AUTOSAR XML (schema 00044)
package /ECUExtractIEM/VehicleProject
  system SDB12010901
    system mapping SDB12010901_MPPNG
      data-mappings:
        sender-receiver-to-signal-group-mapping={data-element=DmcStsRearToEsc.DmcStsRearToEsc, signal-group=DmcStsRearToEsc, type-mapping=sender-rec-record-type-mapping=record-element-mappings=[{application-record-element=DmcSts, system-signal=DmcStsRearToEscDmcSts}, {application-record-element=Chks, system-signal=DmcStsRearToEscChks}, {application-record-element=Cntr, system-signal=DmcStsRearToEscCntr}, {application-record-element=DmcActAppTarTq, system-signal=DmcStsRearToEscDmcActAppTarTq}, {application-record-element=DmcSWInfo, system-signal=DmcStsRearToEscDmcSWInfo}]}
        sender-receiver-to-signal-group-mapping={data-element=IemGeneric.IemGeneric, signal-group=IemGeneric, type-mapping=sender-rec-record-type-mapping=record-element-mappings=[{application-record-element=FltAlrmSt, system-signal=IemGenericFltAlrmSt}, {application-record-element=ModStatusRms, system-signal=IemGenericModStatusRms}, {application-record-element=IacAlrmSt, system-signal=IemGenericIacAlrmSt}, {application-record-element=EMSeqNr, system-signal=IemGenericEMSeqNr}, {application-record-element=SpdAlrmSt, system-signal=IemGenericSpdAlrmSt}, {application-record-element=MotTAlrmSt, system-signal=IemGenericMotTAlrmSt}, {application-record-element=UDcAlrmSt, system-signal=IemGenericUDcAlrmSt}, {application-record-element=EMQnty, system-signal=IemGenericEMQnty}, {application-record-element=InvrtTAlrmSt, system-signal=IemGenericInvrtTAlrmSt}, {application-record-element=ADAlrmSt, system-signal=IemGenericADAlrmSt}, {application-record-element=DTCHig, system-signal=IemGenericDTCHig}, {application-record-element=DTCLow, system-signal=IemGenericDTCLow}, {application-record-element=RslAlrmSt, system-signal=IemGenericRslAlrmSt}, {application-record-element=DTCMid, system-signal=IemGenericDTCMid}, {application-record-element=DTCSts, system-signal=IemGenericDTCSts}, {application-record-element=TypeInfo, system-signal=IemGenericTypeInfo}]}
        sender-receiver-to-signal-group-mapping={data-element=IEMTestFr1.IEMTestFr1, signal-group=IEMTestFr1, type-mapping=sender-rec-record-type-mapping=record-element-mappings=[{application-record-element=Byte7, system-signal=IEMTestFr1Byte7}, {application-record-element=Byte2, system-signal=IEMTestFr1Byte2}, {application-record-element=Byte6, system-signal=IEMTestFr1Byte6}, {application-record-element=Byte4, system-signal=IEMTestFr1Byte4}, {application-record-element=Byte3, system-signal=IEMTestFr1Byte3}, {application-record-element=Byte1, system-signal=IEMTestFr1Byte1}, {application-record-element=Byte0, system-signal=IEMTestFr1Byte0}, {application-record-element=Byte5, system-signal=IEMTestFr1Byte5}]}
        sender-receiver-to-signal-group-mapping={data-element=IEMTestFr2.IEMTestFr2, signal-group=IEMTestFr2, type-mapping=sender-rec-record-type-mapping=record-element-mappings=[{application-record-element=Byte2, system-signal=IEMTestFr2Byte2}, {application-record-element=Byte3, system-signal=IEMTestFr2Byte3}, {application-record-element=Byte5, system-signal=IEMTestFr2Byte5}, {application-record-element=Byte7, system-signal=IEMTestFr2Byte7}, {application-record-element=Byte6, system-signal=IEMTestFr2Byte6}, {application-record-element=Byte4, system-signal=IEMTestFr2Byte4}, {application-record-element=Byte1, system-signal=IEMTestFr2Byte1}, {application-record-element=Byte0, system-signal=IEMTestFr2Byte0}]}
        sender-receiver-to-signal-group-mapping={data-element=IEMTestFr3.IEMTestFr3, signal-group=IEMTestFr3, type-mapping=sender-rec-record-type-mapping=record-element-mappings=[{application-record-element=Byte0, system-signal=IEMTestFr3Byte0}, {application-record-element=Byte4, system-signal=IEMTestFr3Byte4}, {application-record-element=Byte5, system-signal=IEMTestFr3Byte5}, {application-record-element=Byte6, system-signal=IEMTestFr3Byte6}, {application-record-element=Byte1, system-signal=IEMTestFr3Byte1}, {application-record-element=Byte7, system-signal=IEMTestFr3Byte7}, {application-record-element=Byte2, system-signal=IEMTestFr3Byte2}, {application-record-element=Byte3, system-signal=IEMTestFr3Byte3}]}
        sender-receiver-to-signal-group-mapping={data-element=ImobEngChk2.ImobEngChk2, signal-group=ImobEngChk2, type-mapping=sender-rec-record-type-mapping=record-element-mappings=[{application-record-element=ImobEngDataChk2, system-signal=ImobEngChk2ImobEngDataChk2}, {application-record-element=ImobEngDataChk3, system-signal=ImobEngChk2ImobEngDataChk3}, {application-record-element=ImobEngDataChk4, system-signal=ImobEngChk2ImobEngDataChk4}, {application-record-element=ImobEngDataChk6, system-signal=ImobEngChk2ImobEngDataChk6}, {application-record-element=ImobEngChkSts, system-signal=ImobEngChk2ImobEngChkSts}, {application-record-element=ImobEngDataChk0, system-signal=ImobEngChk2ImobEngDataChk0}, {application-record-element=ImobEngDataChk5, system-signal=ImobEngChk2ImobEngDataChk5}, {application-record-element=ImobEngDataChk1, system-signal=ImobEngChk2ImobEngDataChk1}]}
        sender-receiver-to-signal-mapping={data-element=ImobEngSts2.ImobEngSts2, system-signal=ImobEngSts2}
        sender-receiver-to-signal-mapping={data-element=PLockFltIndcRe.PLockFltIndcRe, system-signal=PLockFltIndcRe}
        sender-receiver-to-signal-mapping={data-element=PLockFltLvlRe.PLockFltLvlRe, system-signal=PLockFltLvlRe}
        sender-receiver-to-signal-mapping={data-element=PLockParkStsRe.PLockParkStsRe, system-signal=PLockParkStsRe}
        sender-receiver-to-signal-mapping={data-element=WhlMotClrRdyReq.WhlMotClrRdyReq, system-signal=WhlMotClrRdyReq}
        sender-receiver-to-signal-mapping={data-element=WhlMotCooltFlowMinReq.WhlMotCooltFlowMinReq, system-signal=WhlMotCooltFlowMinReq}
        sender-receiver-to-signal-mapping={data-element=WhlMotSysCoolgReq.WhlMotSysCoolgReq, system-signal=WhlMotSysCoolgReq}
        sender-receiver-to-signal-mapping={data-element=WhlMotSysCooltT.WhlMotSysCooltT, system-signal=WhlMotSysCooltT}
        sender-receiver-to-signal-mapping={data-element=WhlMotSysErrIndcnReq.WhlMotSysErrIndcnReq, system-signal=WhlMotSysErrIndcnReq}
        sender-receiver-to-signal-mapping={data-element=WhlMotSysHeatFdBck.WhlMotSysHeatFdBck, system-signal=WhlMotSysHeatFdBck}
        sender-receiver-to-signal-mapping={data-element=WhlMotSysHeatPwrAct.WhlMotSysHeatPwrAct, system-signal=WhlMotSysHeatPwrAct}
        sender-receiver-to-signal-mapping={data-element=WhlMotSysHeatPwrMax.WhlMotSysHeatPwrMax, system-signal=WhlMotSysHeatPwrMax}
        sender-receiver-to-signal-mapping={data-element=WhlMotSysIdc.WhlMotSysIdc, system-signal=WhlMotSysIdc}
        sender-receiver-to-signal-mapping={data-element=WhlMotSysInvrT.WhlMotSysInvrT, system-signal=WhlMotSysInvrT}
        sender-receiver-to-signal-mapping={data-element=WhlMotSysLimnIndcn.WhlMotSysLimnIndcn, system-signal=WhlMotSysLimnIndcn}
        sender-receiver-to-signal-mapping={data-element=WhlMotSysModSts.WhlMotSysModSts, system-signal=WhlMotSysModSts}
        sender-receiver-to-signal-mapping={data-element=WhlMotSysMotT.WhlMotSysMotT, system-signal=WhlMotSysMotT}
        sender-receiver-to-signal-mapping={data-element=WhlMotSysSpdAct.WhlMotSysSpdAct, system-signal=WhlMotSysSpdAct}
        sender-receiver-to-signal-group-mapping={data-element=WhlMotSysSpdActSafe.WhlMotSysSpdActSafe, signal-group=WhlMotSysSpdActSafe, type-mapping=sender-rec-record-type-mapping=record-element-mappings=[{application-record-element=Chks, system-signal=WhlMotSysSpdActSafeChks}, {application-record-element=IsgSpdWSgnTyp, system-signal=WhlMotSysSpdActSafeIsgSpdWSgnTyp}, {application-record-element=Qf, system-signal=WhlMotSysSpdActSafeQf}, {application-record-element=Cntr, system-signal=WhlMotSysSpdActSafeCntr}]}
        sender-receiver-to-signal-group-mapping={data-element=WhlMotSysTqAvl.WhlMotSysTqAvl, signal-group=WhlMotSysTqAvl, type-mapping=sender-rec-record-type-mapping=record-element-mappings=[{application-record-element=TqAvlMin, system-signal=WhlMotSysTqAvlTqAvlMin}, {application-record-element=TqAvlMax, system-signal=WhlMotSysTqAvlTqAvlMax}]}
        sender-receiver-to-signal-group-mapping={data-element=WhlMotSysTqEst.WhlMotSysTqEst, signal-group=WhlMotSysTqEst, type-mapping=sender-rec-record-type-mapping=record-element-mappings=[{application-record-element=Cntr, system-signal=WhlMotSysTqEstCntr}, {application-record-element=IsgTqAct, system-signal=WhlMotSysTqEstIsgTqAct}, {application-record-element=QualityFactor, system-signal=WhlMotSysTqEstQualityFactor}, {application-record-element=Chks, system-signal=WhlMotSysTqEstChks}]}
        sender-receiver-to-signal-mapping={data-element=WhlMotSysUdc.WhlMotSysUdc, system-signal=WhlMotSysUdc}
        sender-receiver-to-signal-mapping={data-element=BkpOfDstTrvld.BkpOfDstTrvld, system-signal=BkpOfDstTrvld}
        sender-receiver-to-signal-mapping={data-element=CarTiGlb.CarTiGlb, system-signal=CarTiGlb}
        sender-receiver-to-signal-mapping={data-element=CooltFlowForDtElec.CooltFlowForDtElec, system-signal=CooltFlowForDtElec}
        sender-receiver-to-signal-mapping={data-element=CooltTSigForDtElec.CooltTSigForDtElec, system-signal=CooltTSigForDtElec}
        sender-receiver-to-signal-group-mapping={data-element=CrashStsSafe.CrashStsSafe, signal-group=CrashStsSafe, type-mapping=sender-rec-record-type-mapping=record-element-mappings=[{application-record-element=Cntr, system-signal=CrashStsSafeCntr}, {application-record-element=Sts, system-signal=CrashStsSafeSts}, {application-record-element=Chks, system-signal=CrashStsSafeChks}]}
        sender-receiver-to-signal-mapping={data-element=DCChrgnHndlSts.DCChrgnHndlSts, system-signal=DCChrgnHndlSts}
        sender-receiver-to-signal-mapping={data-element=DrvgCyc.DrvgCyc, system-signal=DrvgCyc}
        sender-receiver-to-signal-group-mapping={data-element=EngSt1WdSts.EngSt1WdSts, signal-group=EngSt1WdSts, type-mapping=sender-rec-record-type-mapping=record-element-mappings=[{application-record-element=Chks, system-signal=EngSt1WdStsChks}, {application-record-element=EngSt1WdSts, system-signal=EngSt1WdStsEngSt1WdSts}, {application-record-element=Cntr, system-signal=EngSt1WdStsCntr}]}
        sender-receiver-to-signal-group-mapping={data-element=EscVariantToDmc.EscVariantToDmc, signal-group=EscVariantToDmc, type-mapping=sender-rec-record-type-mapping=record-element-mappings=[{application-record-element=Chks, system-signal=EscVariantToDmcChks}, {application-record-element=EscVariantToDmc, system-signal=EscVariantToDmcEscVariantToDmc}, {application-record-element=Cntr, system-signal=EscVariantToDmcCntr}]}
        sender-receiver-to-signal-mapping={data-element=GearLvrIndcn.GearLvrIndcn, system-signal=GearLvrIndcn}
        sender-receiver-to-signal-mapping={data-element=HvBattSoc.HvBattSoc, system-signal=HvBattSoc}
        sender-receiver-to-signal-mapping={data-element=HvBattUDc.HvBattUDc, system-signal=HvBattUDc}
        sender-receiver-to-signal-mapping={data-element=HvBattUDynMaxLim.HvBattUDynMaxLim, system-signal=HvBattUDynMaxLim}
        sender-receiver-to-signal-mapping={data-element=HvBattUDynMinLim.HvBattUDynMinLim, system-signal=HvBattUDynMinLim}
        sender-receiver-to-signal-group-mapping={data-element=HvSysRlySts.HvSysRlySts, signal-group=HvSysRlySts, type-mapping=sender-rec-record-type-mapping=record-element-mappings=[{application-record-element=Chks, system-signal=HvSysRlyStsChks}, {application-record-element=HvSysRlySts, system-signal=HvSysRlyStsHvSysRlySts}, {application-record-element=Cntr, system-signal=HvSysRlyStsCntr}]}
        sender-receiver-to-signal-group-mapping={data-element=ImobEngMgrReq2.ImobEngMgrReq2, signal-group=ImobEngMgrReq2, type-mapping=sender-rec-record-type-mapping=record-element-mappings=[{application-record-element=ImobEngDataMgrReq4, system-signal=ImobEngMgrReq2ImobEngDataMgrReq4}, {application-record-element=ImobEngMgrCmdTar1, system-signal=ImobEngMgrReq2ImobEngMgrCmdTar1}, {application-record-element=ImobEngDataMgrReq3, system-signal=ImobEngMgrReq2ImobEngDataMgrReq3}, {application-record-element=ImobEngDataMgrReq2, system-signal=ImobEngMgrReq2ImobEngDataMgrReq2}, {application-record-element=ImobEngDataMgrReq0, system-signal=ImobEngMgrReq2ImobEngDataMgrReq0}, {application-record-element=ImobEngDataMgrReq5, system-signal=ImobEngMgrReq2ImobEngDataMgrReq5}, {application-record-element=ImobEngDataMgrReq6, system-signal=ImobEngMgrReq2ImobEngDataMgrReq6}, {application-record-element=ImobEngDataMgrReq1, system-signal=ImobEngMgrReq2ImobEngDataMgrReq1}]}
        sender-receiver-to-signal-mapping={data-element=OnBdChrgrHndlSts1.OnBdChrgrHndlSts1, system-signal=OnBdChrgrHndlSts1}
        sender-receiver-to-signal-mapping={data-element=PLockParkReq.PLockParkReq, system-signal=PLockParkReq}
        sender-receiver-to-signal-mapping={data-element=PrpsnFbLimnIndcn.PrpsnFbLimnIndcn, system-signal=PrpsnFbLimnIndcn}
        sender-receiver-to-signal-group-mapping={data-element=PtTqAtAxleMaxReq.PtTqAtAxleMaxReq, signal-group=PtTqAtAxleMaxReq, type-mapping=sender-rec-record-type-mapping=record-element-mappings=[{application-record-element=Chks, system-signal=PtTqAtAxleMaxReqChks}, {application-record-element=PtTqAtAxleFrntReq, system-signal=PtTqAtAxleMaxReqPtTqAtAxleFrntReq}, {application-record-element=Cntr, system-signal=PtTqAtAxleMaxReqCntr}, {application-record-element=PtTqAtAxleReReq, system-signal=PtTqAtAxleMaxReqPtTqAtAxleReReq}]}
        sender-receiver-to-signal-mapping={data-element=RearHeatModEnad.RearHeatModEnad, system-signal=RearHeatModEnad}
        sender-receiver-to-signal-mapping={data-element=RearHeatPwrAllwd.RearHeatPwrAllwd, system-signal=RearHeatPwrAllwd}
        sender-receiver-to-signal-mapping={data-element=SpdRotlForWhlsAtAxleRe.SpdRotlForWhlsAtAxleRe, system-signal=SpdRotlForWhlsAtAxleRe}
        sender-receiver-to-signal-group-mapping={data-element=StcStsToDmc.StcStsToDmc, signal-group=StcStsToDmc, type-mapping=sender-rec-record-type-mapping=record-element-mappings=[{application-record-element=EngRotTarSpdDMCFrnt, system-signal=StcStsToDmcEngRotTarSpdDMCFrnt}, {application-record-element=StcStsToDmcFrnt, system-signal=StcStsToDmcFrnt}, {application-record-element=EngRotTarSpdDMCRear, system-signal=StcStsToDmcEngRotTarSpdDMCRear}, {application-record-element=Chks, system-signal=StcStsToDmcChks}, {application-record-element=Cntr, system-signal=StcStsToDmcCntr}, {application-record-element=StcStsToDmcRear, system-signal=StcStsToDmcRear}]}
        sender-receiver-to-signal-group-mapping={data-element=VehBattU.VehBattU, signal-group=VehBattU, type-mapping=sender-rec-record-type-mapping=record-element-mappings=[{application-record-element=SysU, system-signal=VehBattUSysU}, {application-record-element=SysUQf, system-signal=VehBattUSysUQf}]}
        sender-receiver-to-signal-group-mapping={data-element=VehCfgPrm.VehCfgPrm, signal-group=VehCfgPrm, type-mapping=sender-rec-record-type-mapping=record-element-mappings=[{application-record-element=CCPBytePosn6, system-signal=VehCfgPrmCCPBytePosn6}, {application-record-element=BlkIDBytePosn1, system-signal=VehCfgPrmBlkIDBytePosn1}, {application-record-element=CCPBytePosn4, system-signal=VehCfgPrmCCPBytePosn4}, {application-record-element=CCPBytePosn3, system-signal=VehCfgPrmCCPBytePosn3}, {application-record-element=CCPBytePosn2, system-signal=VehCfgPrmCCPBytePosn2}, {application-record-element=CCPBytePosn8, system-signal=VehCfgPrmCCPBytePosn8}, {application-record-element=CCPBytePosn7, system-signal=VehCfgPrmCCPBytePosn7}, {application-record-element=CCPBytePosn5, system-signal=VehCfgPrmCCPBytePosn5}]}
        sender-receiver-to-signal-group-mapping={data-element=VehCfgPrmExt.VehCfgPrmExt, signal-group=VehCfgPrmExt, type-mapping=sender-rec-record-type-mapping=record-element-mappings=[{application-record-element=CCPBytePosn5, system-signal=VehCfgPrmExtCCPBytePosn5}, {application-record-element=CCPBytePosn6, system-signal=VehCfgPrmExtCCPBytePosn6}, {application-record-element=CCPBytePosn2, system-signal=VehCfgPrmExtCCPBytePosn2}, {application-record-element=CCPBytePosn3, system-signal=VehCfgPrmExtCCPBytePosn3}, {application-record-element=CCPBytePosn8, system-signal=VehCfgPrmExtCCPBytePosn8}, {application-record-element=CCPBytePosn4, system-signal=VehCfgPrmExtCCPBytePosn4}, {application-record-element=CCPBytePosn7, system-signal=VehCfgPrmExtCCPBytePosn7}, {application-record-element=BlkIDBytePosn1, system-signal=VehCfgPrmExtBlkIDBytePosn1}]}
        sender-receiver-to-signal-group-mapping={data-element=VehModMngtGlbSafe1.VehModMngtGlbSafe1, signal-group=VehModMngtGlbSafe1, type-mapping=sender-rec-record-type-mapping=record-element-mappings=[{application-record-element=Chks, system-signal=VehModMngtGlbSafe1Chks}, {application-record-element=CarModSts1, system-signal=VehModMngtGlbSafe1CarModSts1}, {application-record-element=Cntr, system-signal=VehModMngtGlbSafe1Cntr}, {application-record-element=EgyLvlElecSubtyp, system-signal=VehModMngtGlbSafe1EgyLvlElecSubtyp}, {application-record-element=PwrLvlElecSubtyp, system-signal=VehModMngtGlbSafe1PwrLvlElecSubtyp}, {application-record-element=CarModSubtypWdCarModSubtyp, system-signal=VehModMngtGlbSafe1CarModSubtypWdCarModSubtyp}, {application-record-element=UsgModSts, system-signal=VehModMngtGlbSafe1UsgModSts}, {application-record-element=PwrLvlElecMai, system-signal=VehModMngtGlbSafe1PwrLvlElecMai}, {application-record-element=EgyLvlElecMai, system-signal=VehModMngtGlbSafe1EgyLvlElecMai}, {application-record-element=FltEgyCnsWdSts, system-signal=VehModMngtGlbSafe1FltEgyCnsWdSts}]}
        sender-receiver-to-signal-group-mapping={data-element=VehMtnSt.VehMtnSt, signal-group=VehMtnSt, type-mapping=sender-rec-record-type-mapping=record-element-mappings=[{application-record-element=VehMtnStChks, system-signal=VehMtnStChks}, {application-record-element=VehMtnStCntr, system-signal=VehMtnStCntr}, {application-record-element=VehMtnSt, system-signal=VehMtnStVehMtnSt}]}
        sender-receiver-to-signal-group-mapping={data-element=VehSpdLgt.VehSpdLgt, signal-group=VehSpdLgt, type-mapping=sender-rec-record-type-mapping=record-element-mappings=[{application-record-element=VehSpdLgtQf, system-signal=VehSpdLgtQf}, {application-record-element=VehSpdLgtCntr, system-signal=VehSpdLgtCntr}, {application-record-element=VehSpdLgtChks, system-signal=VehSpdLgtChks}, {application-record-element=VehSpdLgtA, system-signal=VehSpdLgtA}]}
        sender-receiver-to-signal-mapping={data-element=WhlMotSysActvDampgModReq.WhlMotSysActvDampgModReq, system-signal=WhlMotSysActvDampgModReq}
        sender-receiver-to-signal-mapping={data-element=WhlMotSysModReq.WhlMotSysModReq, system-signal=WhlMotSysModReq}
        sender-receiver-to-signal-mapping={data-element=WhlMotSysPwrLimMax.WhlMotSysPwrLimMax, system-signal=WhlMotSysPwrLimMax}
        sender-receiver-to-signal-mapping={data-element=WhlMotSysPwrLimMin.WhlMotSysPwrLimMin, system-signal=WhlMotSysPwrLimMin}
        sender-receiver-to-signal-group-mapping={data-element=WhlMotSysTqAllwd.WhlMotSysTqAllwd, signal-group=WhlMotSysTqAllwd, type-mapping=sender-rec-record-type-mapping=record-element-mappings=[{application-record-element=WhlMotSysTqAllwd, system-signal=WhlMotSysTqAllwdWhlMotSysTqAllwd}, {application-record-element=Chks, system-signal=WhlMotSysTqAllwdChks}, {application-record-element=Cntr, system-signal=WhlMotSysTqAllwdCntr}]}
        sender-receiver-to-signal-mapping={data-element=WhlMotSysTqReq.WhlMotSysTqReq, system-signal=WhlMotSysTqReq}
      pnc-mappings:
        pnc-group=TxSPG_PropulsionCAN_PNC16, pnc-identifier=16, vfc=TopLevelComposition.InfotainmentPush
        pnc-group=[TxSPG_PropulsionCAN_PNC24, RxSPG_PropulsionCAN_PNC24], pnc-identifier=24, vfc=TopLevelComposition.PropulsionStart
        pnc-group=[TxSPG_PropulsionCAN_PNC25, RxSPG_PropulsionCAN_PNC25], pnc-identifier=25, vfc=TopLevelComposition.ChargingHV
        pnc-group=[TxSPG_PropulsionCAN_PNC26, RxSPG_PropulsionCAN_PNC26], pnc-identifier=26, vfc=[TopLevelComposition.ParkingDrivingClimatization, TopLevelComposition.Immobilizer]
        pnc-group=[TxSPG_PropulsionCAN_PNC27, RxSPG_PropulsionCAN_PNC27], pnc-identifier=27, vfc=TopLevelComposition.TelematicsConnectivity
        pnc-group=[TxSPG_PropulsionCAN_PNC29, RxSPG_PropulsionCAN_PNC29], pnc-identifier=29, vfc=[TopLevelComposition.Diagnostics, TopLevelComposition.VehicleDriving, TopLevelComposition.VehicleModeManagement]
        pnc-group=[TxSPG_PropulsionCAN_PNC30, RxSPG_PropulsionCAN_PNC30], pnc-identifier=30, vfc=TopLevelComposition.GlobalShortDuration
        pnc-group=TxSPG_PropulsionCAN_PNC33, pnc-identifier=33, vfc=TopLevelComposition.Brake
        pnc-group=[TxSPG_PropulsionCAN_PNC35, RxSPG_PropulsionCAN_PNC35], pnc-identifier=35, vfc=TopLevelComposition.HVEnergyStorage
        pnc-group=[TxSPG_PropulsionCAN_PNC39, RxSPG_PropulsionCAN_PNC39], pnc-identifier=39, vfc=TopLevelComposition.Crash
    root-software-compositions:
      root sw composition prototype TopLevelComposition: software-composition=TopLevelComposition
package /ECUExtractIEM/ComponentType
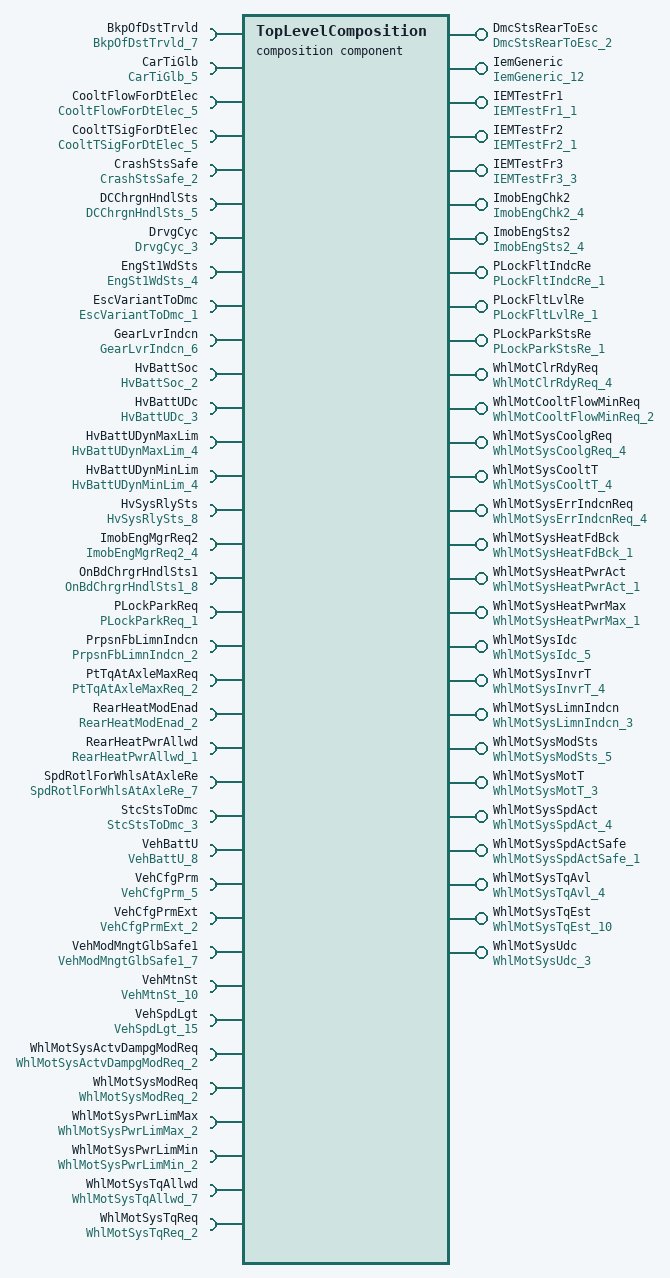
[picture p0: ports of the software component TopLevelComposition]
  composition sw component type TopLevelComposition
    28 x provide port:
      DmcStsRearToEsc: provided-interface=DmcStsRearToEsc_2
      IemGeneric: provided-interface=IemGeneric_12
      IEMTestFr1: provided-interface=IEMTestFr1_1
      IEMTestFr2: provided-interface=IEMTestFr2_1
      IEMTestFr3: provided-interface=IEMTestFr3_3
      ImobEngChk2: provided-interface=ImobEngChk2_4
      ImobEngSts2: provided-interface=ImobEngSts2_4
      PLockFltIndcRe: provided-interface=PLockFltIndcRe_1
      PLockFltLvlRe: provided-interface=PLockFltLvlRe_1
      PLockParkStsRe: provided-interface=PLockParkStsRe_1
      WhlMotClrRdyReq: provided-interface=WhlMotClrRdyReq_4
      WhlMotCooltFlowMinReq: provided-interface=WhlMotCooltFlowMinReq_2
      WhlMotSysCoolgReq: provided-interface=WhlMotSysCoolgReq_4
      WhlMotSysCooltT: provided-interface=WhlMotSysCooltT_4
      WhlMotSysErrIndcnReq: provided-interface=WhlMotSysErrIndcnReq_4
      WhlMotSysHeatFdBck: provided-interface=WhlMotSysHeatFdBck_1
      WhlMotSysHeatPwrAct: provided-interface=WhlMotSysHeatPwrAct_1
      WhlMotSysHeatPwrMax: provided-interface=WhlMotSysHeatPwrMax_1
      WhlMotSysIdc: provided-interface=WhlMotSysIdc_5
      WhlMotSysInvrT: provided-interface=WhlMotSysInvrT_4
      WhlMotSysLimnIndcn: provided-interface=WhlMotSysLimnIndcn_3
      WhlMotSysModSts: provided-interface=WhlMotSysModSts_5
      WhlMotSysMotT: provided-interface=WhlMotSysMotT_3
      WhlMotSysSpdAct: provided-interface=WhlMotSysSpdAct_4
      WhlMotSysSpdActSafe: provided-interface=WhlMotSysSpdActSafe_1
      WhlMotSysTqAvl: provided-interface=WhlMotSysTqAvl_4
      WhlMotSysTqEst: provided-interface=WhlMotSysTqEst_10
      WhlMotSysUdc: provided-interface=WhlMotSysUdc_3
    36 x require port:
      BkpOfDstTrvld: required-interface=BkpOfDstTrvld_7
      CarTiGlb: required-interface=CarTiGlb_5
      CooltFlowForDtElec: required-interface=CooltFlowForDtElec_5
      CooltTSigForDtElec: required-interface=CooltTSigForDtElec_5
      CrashStsSafe: required-interface=CrashStsSafe_2
      DCChrgnHndlSts: required-interface=DCChrgnHndlSts_5
      DrvgCyc: required-interface=DrvgCyc_3
      EngSt1WdSts: required-interface=EngSt1WdSts_4
      EscVariantToDmc: required-interface=EscVariantToDmc_1
      GearLvrIndcn: required-interface=GearLvrIndcn_6
      HvBattSoc: required-interface=HvBattSoc_2
      HvBattUDc: required-interface=HvBattUDc_3
      HvBattUDynMaxLim: required-interface=HvBattUDynMaxLim_4
      HvBattUDynMinLim: required-interface=HvBattUDynMinLim_4
      HvSysRlySts: required-interface=HvSysRlySts_8
      ImobEngMgrReq2: required-interface=ImobEngMgrReq2_4
      OnBdChrgrHndlSts1: required-interface=OnBdChrgrHndlSts1_8
      PLockParkReq: required-interface=PLockParkReq_1
      PrpsnFbLimnIndcn: required-interface=PrpsnFbLimnIndcn_2
      PtTqAtAxleMaxReq: required-interface=PtTqAtAxleMaxReq_2
      RearHeatModEnad: required-interface=RearHeatModEnad_2
      RearHeatPwrAllwd: required-interface=RearHeatPwrAllwd_1
      SpdRotlForWhlsAtAxleRe: required-interface=SpdRotlForWhlsAtAxleRe_7
      StcStsToDmc: required-interface=StcStsToDmc_3
      VehBattU: required-interface=VehBattU_8
      VehCfgPrm: required-interface=VehCfgPrm_5
      VehCfgPrmExt: required-interface=VehCfgPrmExt_2
      VehModMngtGlbSafe1: required-interface=VehModMngtGlbSafe1_7
      VehMtnSt: required-interface=VehMtnSt_10
      VehSpdLgt: required-interface=VehSpdLgt_15
      WhlMotSysActvDampgModReq: required-interface=WhlMotSysActvDampgModReq_2
      WhlMotSysModReq: required-interface=WhlMotSysModReq_2
      WhlMotSysPwrLimMax: required-interface=WhlMotSysPwrLimMax_2
      WhlMotSysPwrLimMin: required-interface=WhlMotSysPwrLimMin_2
      WhlMotSysTqAllwd: required-interface=WhlMotSysTqAllwd_7
      WhlMotSysTqReq: required-interface=WhlMotSysTqReq_2
    13 x port group, all with category=PARTIAL_NETWORKING:
      ParkingDrivingClimatization: inner-group=IEM.ParkingDrivingClimatization
      Diagnostics: inner-group=IEM.Diagnostics
      VehicleDriving: inner-group=IEM.VehicleDriving
      VehicleModeManagement: inner-group=IEM.VehicleModeManagement
      TelematicsConnectivity: inner-group=IEM.TelematicsConnectivity
      HVEnergyStorage: inner-group=IEM.HVEnergyStorage
      Crash: inner-group=IEM.Crash
      InfotainmentPush: inner-group=IEM.InfotainmentPush
      PropulsionStart: inner-group=IEM.PropulsionStart
      GlobalShortDuration: inner-group=IEM.GlobalShortDuration
      Brake: inner-group=IEM.Brake
      ChargingHV: inner-group=IEM.ChargingHV
      Immobilizer: inner-group=IEM.Immobilizer
    component IEM: type=IEM
    delegate IEM.DmcStsRearToEsc <-> outer port DmcStsRearToEsc
    delegate IEM.IemGeneric <-> outer port IemGeneric
    delegate IEM.IEMTestFr{1..3} <-> outer port IEMTestFr{1..3}
    delegate IEM.ImobEngChk2 <-> outer port ImobEngChk2
    delegate IEM.ImobEngSts2 <-> outer port ImobEngSts2
    delegate IEM.PLockFltIndcRe <-> outer port PLockFltIndcRe
    delegate IEM.PLockFltLvlRe <-> outer port PLockFltLvlRe
    delegate IEM.PLockParkStsRe <-> outer port PLockParkStsRe
    delegate IEM.WhlMotClrRdyReq <-> outer port WhlMotClrRdyReq
    delegate IEM.WhlMotCooltFlowMinReq <-> outer port WhlMotCooltFlowMinReq
    delegate IEM.WhlMotSysCoolgReq <-> outer port WhlMotSysCoolgReq
    delegate IEM.WhlMotSysCooltT <-> outer port WhlMotSysCooltT
    delegate IEM.WhlMotSysErrIndcnReq <-> outer port WhlMotSysErrIndcnReq
    delegate IEM.WhlMotSysHeatFdBck <-> outer port WhlMotSysHeatFdBck
    delegate IEM.WhlMotSysHeatPwrAct <-> outer port WhlMotSysHeatPwrAct
    delegate IEM.WhlMotSysHeatPwrMax <-> outer port WhlMotSysHeatPwrMax
    delegate IEM.WhlMotSysIdc <-> outer port WhlMotSysIdc
    delegate IEM.WhlMotSysInvrT <-> outer port WhlMotSysInvrT
    delegate IEM.WhlMotSysLimnIndcn <-> outer port WhlMotSysLimnIndcn
    delegate IEM.WhlMotSysModSts <-> outer port WhlMotSysModSts
    delegate IEM.WhlMotSysMotT <-> outer port WhlMotSysMotT
    delegate IEM.WhlMotSysSpdAct <-> outer port WhlMotSysSpdAct
    delegate IEM.WhlMotSysSpdActSafe <-> outer port WhlMotSysSpdActSafe
    delegate IEM.WhlMotSysTqAvl <-> outer port WhlMotSysTqAvl
    delegate IEM.WhlMotSysTqEst <-> outer port WhlMotSysTqEst
    delegate IEM.WhlMotSysUdc <-> outer port WhlMotSysUdc
    delegate IEM.BkpOfDstTrvld <-> outer port BkpOfDstTrvld
    delegate IEM.CarTiGlb <-> outer port CarTiGlb
    delegate IEM.CooltFlowForDtElec <-> outer port CooltFlowForDtElec
    delegate IEM.CooltTSigForDtElec <-> outer port CooltTSigForDtElec
    delegate IEM.CrashStsSafe <-> outer port CrashStsSafe
    delegate IEM.DCChrgnHndlSts <-> outer port DCChrgnHndlSts
    delegate IEM.DrvgCyc <-> outer port DrvgCyc
    delegate IEM.EngSt1WdSts <-> outer port EngSt1WdSts
    delegate IEM.EscVariantToDmc <-> outer port EscVariantToDmc
    delegate IEM.GearLvrIndcn <-> outer port GearLvrIndcn
    delegate IEM.HvBattSoc <-> outer port HvBattSoc
    delegate IEM.HvBattUDc <-> outer port HvBattUDc
    delegate IEM.HvBattUDynMaxLim <-> outer port HvBattUDynMaxLim
    delegate IEM.HvBattUDynMinLim <-> outer port HvBattUDynMinLim
    delegate IEM.HvSysRlySts <-> outer port HvSysRlySts
    delegate IEM.ImobEngMgrReq2 <-> outer port ImobEngMgrReq2
    delegate IEM.OnBdChrgrHndlSts1 <-> outer port OnBdChrgrHndlSts1
    delegate IEM.PLockParkReq <-> outer port PLockParkReq
    delegate IEM.PrpsnFbLimnIndcn <-> outer port PrpsnFbLimnIndcn
    delegate IEM.PtTqAtAxleMaxReq <-> outer port PtTqAtAxleMaxReq
    delegate IEM.RearHeatModEnad <-> outer port RearHeatModEnad
    delegate IEM.RearHeatPwrAllwd <-> outer port RearHeatPwrAllwd
    delegate IEM.SpdRotlForWhlsAtAxleRe <-> outer port SpdRotlForWhlsAtAxleRe
    delegate IEM.StcStsToDmc <-> outer port StcStsToDmc
    delegate IEM.VehBattU <-> outer port VehBattU
    delegate IEM.VehCfgPrm <-> outer port VehCfgPrm
    delegate IEM.VehCfgPrmExt <-> outer port VehCfgPrmExt
    delegate IEM.VehModMngtGlbSafe1 <-> outer port VehModMngtGlbSafe1
    delegate IEM.VehMtnSt <-> outer port VehMtnSt
    delegate IEM.VehSpdLgt <-> outer port VehSpdLgt
    delegate IEM.WhlMotSysActvDampgModReq <-> outer port WhlMotSysActvDampgModReq
    delegate IEM.WhlMotSysModReq <-> outer port WhlMotSysModReq
    delegate IEM.WhlMotSysPwrLimMax <-> outer port WhlMotSysPwrLimMax
    delegate IEM.WhlMotSysPwrLimMin <-> outer port WhlMotSysPwrLimMin
    delegate IEM.WhlMotSysTqAllwd <-> outer port WhlMotSysTqAllwd
    delegate IEM.WhlMotSysTqReq <-> outer port WhlMotSysTqReq
package /EndToEnds
  end to end protection set MainEndToEndSet
    10 x end to end protection, all with end-to-end-profile=category=PROFILE_G:
      HvSysRlySts_BECM1_IEM: end-to-end-protection-variable-prototype=receiver=TopLevelComposition.HvSysRlySts.HvSysRlySts
      WhlMotSysTqAllwd_ECM3_IEM: end-to-end-protection-variable-prototype=receiver=TopLevelComposition.WhlMotSysTqAllwd.WhlMotSysTqAllwd
      DmcStsRearToEsc_IEM_VDDM: end-to-end-protection-variable-prototype=TopLevelComposition.DmcStsRearToEsc.DmcStsRearToEsc
      WhlMotSysTqEst_IEM_ECM3: end-to-end-protection-variable-prototype=TopLevelComposition.WhlMotSysTqEst.WhlMotSysTqEst
      WhlMotSysSpdActSafe_IEM_BBMRoot: end-to-end-protection-variable-prototype=TopLevelComposition.WhlMotSysSpdActSafe.WhlMotSysSpdActSafe
      CrashStsSafe_SRS_IEM: end-to-end-protection-variable-prototype=receiver=TopLevelComposition.CrashStsSafe.CrashStsSafe
      VehMtnSt_VDDM_IEM: end-to-end-protection-variable-prototype=receiver=TopLevelComposition.VehMtnSt.VehMtnSt
      VehSpdLgt_VDDM_IEM: end-to-end-protection-variable-prototype=receiver=TopLevelComposition.VehSpdLgt.VehSpdLgt
      StcStsToDmc_VDDM_IEM: end-to-end-protection-variable-prototype=receiver=TopLevelComposition.StcStsToDmc.StcStsToDmc
      EscVariantToDmc_VDDM_IEM: end-to-end-protection-variable-prototype=receiver=TopLevelComposition.EscVariantToDmc.EscVariantToDmc
